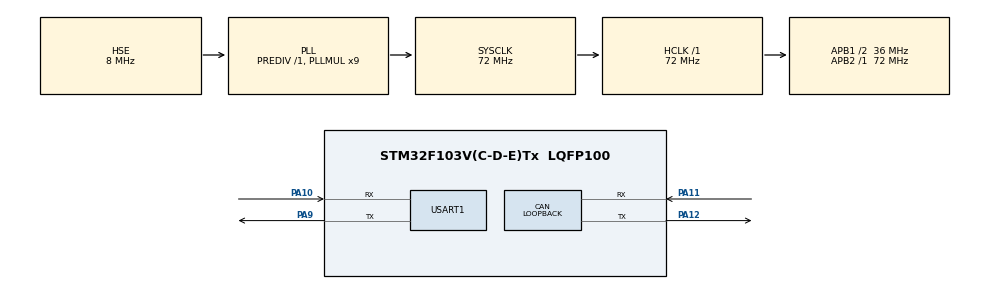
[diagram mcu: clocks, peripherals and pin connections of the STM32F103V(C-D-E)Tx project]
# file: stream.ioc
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CAN.CalculateTimeBit=1333
CAN.CalculateTimeQuantum=444.44444444444446
CAN.Mode=CAN_MODE_LOOPBACK
FREERTOS.Mutexes01=driverMutex,Static,driverMuxtexControlBlock
FREERTOS.Tasks01=defaultTask,24,128,StartDefaultTask,Default,NULL,Dynamic,NULL,NULL
Mcu.Family=STM32F1
Mcu.Name=STM32F103V(C-D-E)Tx
Mcu.Package=LQFP100
NVIC.PriorityGroup=NVIC_PRIORITYGROUP_4
NVIC.TIM1_UP_IRQn=true\:0\:0\:false\:false\:true\:false\:false\:true
NVIC.TimeBase=TIM1_UP_IRQn
NVIC.TimeBaseIP=TIM1
OSC_IN.Mode=HSE-External-Oscillator
OSC_IN.Signal=RCC_OSC_IN
OSC_OUT.Mode=HSE-External-Oscillator
OSC_OUT.Signal=RCC_OSC_OUT
PA10.Mode=Asynchronous
PA10.Signal=USART1_RX
PA11.Mode=Master
PA11.Signal=CAN_RX
PA12.Mode=Master
PA12.Signal=CAN_TX
PA13.Mode=Serial_Wire
PA13.Signal=SYS_JTMS-SWDIO
PA14.Mode=Serial_Wire
PA14.Signal=SYS_JTCK-SWCLK
PA9.Mode=Asynchronous
PA9.Signal=USART1_TX
ProjectManager.HeapSize=0x200
ProjectManager.StackSize=0x400
ProjectManager.TargetToolchain=STM32CubeIDE
RCC.AHBFreq_Value=72000000
RCC.APB1CLKDivider=RCC_HCLK_DIV2
RCC.APB1Freq_Value=36000000
RCC.APB1TimFreq_Value=72000000
RCC.APB2Freq_Value=72000000
RCC.APB2TimFreq_Value=72000000
RCC.HCLKFreq_Value=72000000
RCC.PLLMUL=RCC_PLL_MUL9
RCC.PLLSourceVirtual=RCC_PLLSOURCE_HSE
RCC.SYSCLKFreq_VALUE=72000000
RCC.SYSCLKSource=RCC_SYSCLKSOURCE_PLLCLK
RCC.USBFreq_Value=72000000
USART1.VirtualMode=VM_ASYNC
VP_FREERTOS_VS_CMSIS_V2.Mode=CMSIS_V2
VP_SYS_VS_tim1.Mode=TIM1
board=custom

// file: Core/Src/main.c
/* USER CODE BEGIN Header */
/**
  ******************************************************************************
  * @file           : main.c
  * @brief          : Main program body
  ******************************************************************************
  * @attention
  *
  * <h2><center>&copy; Copyright (c) 2020 STMicroelectronics.
  * All rights reserved.</center></h2>
  *
  * This software component is licensed by ST under BSD 3-Clause license,
  * the "License"; You may not use this file except in compliance with the
  * License. You may obtain a copy of the License at:
  *                        opensource.org/licenses/BSD-3-Clause
  *
  ******************************************************************************
  */
/* USER CODE END Header */

#include "main.h"
#include "cmsis_os.h"

/* USER CODE BEGIN Includes */
#include "packagedriver.h"
/* USER CODE END Includes */

typedef StaticSemaphore_t osStaticMutexDef_t;

CAN_HandleTypeDef hcan;

UART_HandleTypeDef huart1;

/* Definitions for defaultTask */
osThreadId_t defaultTaskHandle;
const osThreadAttr_t defaultTask_attributes = {
  .name = "defaultTask",
  .priority = (osPriority_t) osPriorityNormal,
  .stack_size = 128 * 4
};
/* Definitions for driverMutex */
osMutexId_t driverMutexHandle;
osStaticMutexDef_t driverMuxtexControlBlock;
const osMutexAttr_t driverMutex_attributes = {
  .name = "driverMutex",
  .cb_mem = &driverMuxtexControlBlock,
  .cb_size = sizeof(driverMuxtexControlBlock),
};

void SystemClock_Config(void);
static void MX_GPIO_Init(void);
static void MX_CAN_Init(void);
static void MX_USART1_UART_Init(void);
void StartDefaultTask(void *argument);

int main(void)
{

  /* MCU Configuration--------------------------------------------------------*/

  /* Reset of all peripherals, Initializes the Flash interface and the Systick. */
  HAL_Init();

  /* Configure the system clock */
  SystemClock_Config();

  /* Initialize all configured peripherals */
  MX_GPIO_Init();
  MX_CAN_Init();
  MX_USART1_UART_Init();

  /* Init scheduler */
  osKernelInitialize();
  /* Create the mutex(es) */
  /* creation of driverMutex */
  driverMutexHandle = osMutexNew(&driverMutex_attributes);

  /* Create the thread(s) */
  /* creation of defaultTask */
  defaultTaskHandle = osThreadNew(StartDefaultTask, NULL, &defaultTask_attributes);

  /* Start scheduler */
  osKernelStart();

  /* We should never get here as control is now taken by the scheduler */
  /* Infinite loop */
  while (1)
  {

  }
}

void SystemClock_Config(void)
{
  RCC_OscInitTypeDef RCC_OscInitStruct = {0};
  RCC_ClkInitTypeDef RCC_ClkInitStruct = {0};

  /** Initializes the CPU, AHB and APB busses clocks
  */
  RCC_OscInitStruct.OscillatorType = RCC_OSCILLATORTYPE_HSE;
  RCC_OscInitStruct.HSEState = RCC_HSE_ON;
  RCC_OscInitStruct.HSEPredivValue = RCC_HSE_PREDIV_DIV1;
  RCC_OscInitStruct.HSIState = RCC_HSI_ON;
  RCC_OscInitStruct.PLL.PLLState = RCC_PLL_ON;
  RCC_OscInitStruct.PLL.PLLSource = RCC_PLLSOURCE_HSE;
  RCC_OscInitStruct.PLL.PLLMUL = RCC_PLL_MUL9;
  if (HAL_RCC_OscConfig(&RCC_OscInitStruct) != HAL_OK)
  {
    Error_Handler();
  }
  /** Initializes the CPU, AHB and APB busses clocks
  */
  RCC_ClkInitStruct.ClockType = RCC_CLOCKTYPE_HCLK|RCC_CLOCKTYPE_SYSCLK
                              |RCC_CLOCKTYPE_PCLK1|RCC_CLOCKTYPE_PCLK2;
  RCC_ClkInitStruct.SYSCLKSource = RCC_SYSCLKSOURCE_PLLCLK;
  RCC_ClkInitStruct.AHBCLKDivider = RCC_SYSCLK_DIV1;
  RCC_ClkInitStruct.APB1CLKDivider = RCC_HCLK_DIV2;
  RCC_ClkInitStruct.APB2CLKDivider = RCC_HCLK_DIV1;

  if (HAL_RCC_ClockConfig(&RCC_ClkInitStruct, FLASH_LATENCY_2) != HAL_OK)
  {
    Error_Handler();
  }
}

static void MX_CAN_Init(void)
{

  hcan.Instance = CAN1;
  hcan.Init.Prescaler = 16;
  hcan.Init.Mode = CAN_MODE_LOOPBACK;
  hcan.Init.SyncJumpWidth = CAN_SJW_1TQ;
  hcan.Init.TimeSeg1 = CAN_BS1_1TQ;
  hcan.Init.TimeSeg2 = CAN_BS2_1TQ;
  hcan.Init.TimeTriggeredMode = DISABLE;
  hcan.Init.AutoBusOff = DISABLE;
  hcan.Init.AutoWakeUp = DISABLE;
  hcan.Init.AutoRetransmission = DISABLE;
  hcan.Init.ReceiveFifoLocked = DISABLE;
  hcan.Init.TransmitFifoPriority = DISABLE;
  if (HAL_CAN_Init(&hcan) != HAL_OK)
  {
    Error_Handler();
  }

}

static void MX_USART1_UART_Init(void)
{

  huart1.Instance = USART1;
  huart1.Init.BaudRate = 115200;
  huart1.Init.WordLength = UART_WORDLENGTH_8B;
  huart1.Init.StopBits = UART_STOPBITS_1;
  huart1.Init.Parity = UART_PARITY_NONE;
  huart1.Init.Mode = UART_MODE_TX_RX;
  huart1.Init.HwFlowCtl = UART_HWCONTROL_NONE;
  huart1.Init.OverSampling = UART_OVERSAMPLING_16;
  if (HAL_UART_Init(&huart1) != HAL_OK)
  {
    Error_Handler();
  }

}

static void MX_GPIO_Init(void)
{

  /* GPIO Ports Clock Enable */
  __HAL_RCC_GPIOA_CLK_ENABLE();

}

/* USER CODE BEGIN 4 */
void dummy_write(char c)
{

}

int dummy_read(void)
{
	return 0;
}
/* USER CODE END 4 */

void StartDefaultTask(void *argument)
{
  /* USER CODE BEGIN 5 */
  char buffer[25];
  data_transfer_t test;
  test.read = &dummy_read;
  test.write = &dummy_write;

  packageDriverInit(&test, driverMutexHandle);
  packageDriverSend("test me, please", 15);

  packageDriverGet(buffer, sizeof(buffer));
  /* Infinite loop */
  for(;;)
  {
    osDelay(1);
  }
  /* USER CODE END 5 */
}

 /**
  * @brief  Period elapsed callback in non blocking mode
  * @note   This function is called  when TIM1 interrupt took place, inside
  * HAL_TIM_IRQHandler(). It makes a direct call to HAL_IncTick() to increment
  * a global variable "uwTick" used as application time base.
  * @param  htim : TIM handle
  * @retval None
  */
void HAL_TIM_PeriodElapsedCallback(TIM_HandleTypeDef *htim)
{
  if (htim->Instance == TIM1) {
    HAL_IncTick();
  }
}

void Error_Handler(void)
{
}

/************************ (C) COPYRIGHT STMicroelectronics *****END OF FILE****/
